# NUC123AE_v1 register map
File version: 1.0
Registers are 32-bit, read-write, reset 0x0 unless marked. A register's access mark holds for its fields unless they carry their own. Offsets are from the block's base; [hi:lo] are bit positions; {n}, {i} and the like mark numbered series; 'fields as' and 'values as' point back to an identical list.

## GP (part 1 of 2) — GP Register Map
Base 0x50004000
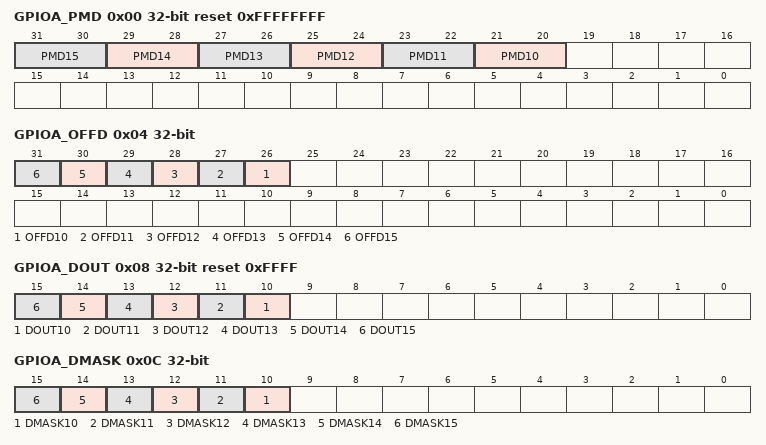
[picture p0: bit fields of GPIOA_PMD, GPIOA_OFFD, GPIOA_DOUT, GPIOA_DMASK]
0x00 GPIOA_PMD reset 0xFFFFFFFF — GPIO Port A Pin I/O Mode Control
  [all] fields
    0=GPIO port [n] pin is in INPUT mode; 1=GPIO port [n] pin is in OUTPUT mode; 2=GPIO port [n] pin is in Open-Drain mode; 3=GPIO port [n] pin is in Quasi-bidirectional mode
  [2n+1:2n] PMD{n} (n=10..15) — GPIOx I/O Pin[n] Mode Control. Determine each I/O type of GPIOx pins. Note: GPIOA: valid n are 15~10. Others are reserved. GPIOB: valid n are 15~12, 10~0. Others are reserved. GPIOC: valid n are 13~8, 5~0. Others are reserved. GPIOD: valid n are 11~8, 5~0. Others are reserved. GPIOF: valid n are 3~0. Others are reserved.
0x04 GPIOA_OFFD — GPIO Port A Pin OFF Digital Enable
  [all] fields
    0=IO digital input path Enabled; 1=IO digital input path Disabled (digital input tied to low)
  [n+16] OFFD{n} (n=10..15) — GPIOx Pin[n] OFF Digital Input Path Enable. Each of these bits is used to control if the input path of corresponding GPIO pin is disabled. If input is analog signal, user can OFF digital input path to avoid creepage. Notes: GPIOA: valid n are 15~10. Others are reserved. GPIOB: valid n are 15~12, 10~0. Others are reserved. GPIOC: valid n are 13~8, 5~0. Others are reserved. GPIOD: valid n are 11~8, 5~0. Others are reserved. GPIOF: valid n are 3~0. Others are reserved.
0x08 GPIOA_DOUT reset 0xFFFF — GPIO Port A Data Output Value
  [all] fields
    0=GPIO port [A/B/C/D/ F] Pin[n] will drive Low if the GPIO pin is configures as output, open-drain and quasi-mode; 1=GPIO port [A/B/C/DF] Pin[n] will drive High if the GPIO pin is configures as output, open-drain and quasi-mode
  [n] DOUT{n} (n=10..15) — GPIOx Pin[n] Output Value. Each of these bits control the status of a GPIO pin when the GPIO pin is configures as output, open-drain and quasi-mode. Note: GPIOA: valid n are 15~10. Others are reserved. GPIOB: valid n are 15~12, 10~0. Others are reserved. GPIOC: valid n are 13~8, 5~0. Others are reserved. GPIOD: valid n are 11~8, 5~0. Others are reserved. GPIOF: valid n are 3~0. Others are reserved.
0x0C GPIOA_DMASK — GPIO Port A Data Output Write Mask
  [all] fields
    0=The corresponding GPIOx_DOUT[n] bit can be updated; 1=The corresponding GPIOx_DOUT[n] bit is protected
  [n] DMASK{n} (n=10..15) — Port [A/B/C/D/ F] Data Output Write Mask. These bits are used to protect the corresponding register of GPIOx_DOUT bit[n]. When set the DMASK bit[n] to 1, the corresponding GPIOx_DOUT[n] bit is protected. The write signal is masked, write data to the protect bit is ignored. Note: This function only protect corresponding GPIOx_DOUT[n] bit, and will not protect corresponding bit control register (GPIOAx_DOUT, GPIOBx_DOUT, GPIOCx_DOUT, GPIODx_DOUT and GPIOFx_DOUT). Note: GPIOA: valid n are 15~10. Others are reserved. GPIOB: valid n are 15~12, 10~0. Others are reserved. GPIOC: valid n are 13~8, 5~0. Others are reserved. GPIOD: valid n are 11~8, 5~0. Others are reserved. GPIOF: valid n are 3~0. Others are reserved.
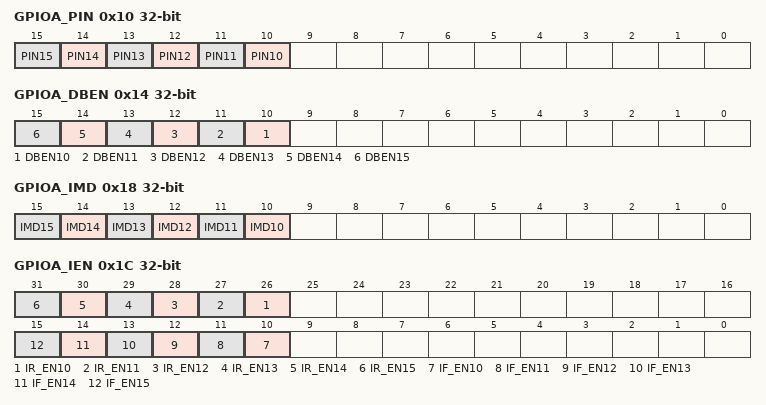
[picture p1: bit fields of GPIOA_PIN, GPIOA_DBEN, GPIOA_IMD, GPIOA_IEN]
0x10 GPIOA_PIN ro (reset mask 0xFFFF0000) — GPIO Port A Pin Value
  [n] PIN{n} (n=10..15) — Port [A/B/C/D/ F] Pin Values. Each bit of the register reflects the actual status of the respective GPIO pin If bit is 1, it indicates the corresponding pin status is high, else the pin status is low. Note: GPIOA: valid n are 15~10. Others are reserved. GPIOB: valid n are 15~12, 10~0. Others are reserved. GPIOC: valid n are 13~8, 5~0. Others are reserved. GPIOD: valid n are 11~8, 5~0. Others are reserved. GPIOF: valid n are 3~0. Others are reserved.
0x14 GPIOA_DBEN — GPIO Port A De-bounce Enable
  [all] fields
    0=The bit[n] de-bounce function is disabled; 1=The bit[n] de-bounce function is enabled
  [n] DBEN{n} (n=10..15) — Port [A/B/C/D/ F] Input Signal De-bounce Enable. DBEN[n]used to enable the de-bounce function for each corresponding bit. If the input signal pulse width can't be sampled by continuous two de-bounce sample cycle The input signal transition is seen as the signal bounce and will not trigger the interrupt. The de-bounce clock source is controlled by DBNCECON[4], one de-bounce sample cycle is controlled by DBNCECON[3:0]. The DBEN[n] is used for "edge-trigger" interrupt only, and ignored for "level trigger" interrupt. The de-bounce function is valid for edge triggered interrupt. If the interrupt mode is level triggered, the de-bounce enable bit is ignored. Note: GPIOA: valid n are 15~10. Others are reserved. GPIOB: valid n are 15~12, 10~0. Others are reserved. GPIOC: valid n are 13~8, 5~0. Others are reserved. GPIOD: valid n are 11~8, 5~0. Others are reserved. GPIOF: valid n are 3~0. Others are reserved.
0x18 GPIOA_IMD — GPIO Port A Interrupt Mode Control
  [all] fields
    0=Edge trigger interrupt; 1=Level trigger interrupt
  [n] IMD{n} (n=10..15) — Port [A/B/C/D/ F] Edge or Level Detection Interrupt Control. IMD[n] is used to control the interrupt is by level trigger or by edge trigger. If the interrupt is by edge trigger, the trigger source can be controlled by de-bounce. If the interrupt is by level trigger, the input source is sampled by one HCLK clock and generates the interrupt. If pin is set as the level trigger interrupt, only one level can be set on the registers GPIOx_IEN. If set both the level to trigger interrupt, the setting is ignored and no interrupt will occur. The de-bounce function is valid for edge triggered interrupt. If the interrupt mode is level triggered, the de-bounce enable bit is ignored. Note: GPIOA: Valid n are 15~10. Others are reserved. GPIOB: Valid n are 15~12, 10~0. Others are reserved. GPIOC: Valid n are 13~8, 5~0. Others are reserved. GPIOD: Valid n are 11~8, 5~0. Others are reserved. GPIOF: Valid n are 3~0. Others are reserved.
0x1C GPIOA_IEN — GPIO Port A Interrupt Enable
  [n+16] IR_EN{n} (n=10..15) — Port [A/B/C/D/ F] Interrupt Enable by Input Rising Edge or Input Level High. IR_EN[n] is used to enable the interrupt for each of the corresponding input GPIO_PIN[n]. Set bit to 1 also enable the pin wake-up function. When the IR_EN[n] bit is set to 1: If the interrupt is level triggered, the input PIN[n] state at level "high" will generate the interrupt. If the interrupt is edge triggered, the input PIN[n] state changes from "low-to-high" will generate the interrupt. Note: GPIOA: Valid n are 15~10. Others are reserved. GPIOB: Valid n are 15~12, 10~0. Others are reserved. GPIOC: Valid n are 13~8, 5~0. Others are reserved. GPIOD: Valid n are 11~8, 5~0. Others are reserved. GPIOF: Valid n are 3~0. Others are reserved.
    0=PIN[n] level-high or low-to-high interrupt Disabled; 1=PIN[n] level-high or low-to-high interrupt Enabled
  [n] IF_EN{n} (n=10..15) — Port [A/B/C/D/ F] Interrupt Enable by Input Falling Edge or Input Level Low. IF_EN[n] is used to enable the interrupt for each of the corresponding input GPIO_PIN[n]. Set bit to 1 also enable the pin wake-up function. When set the IF_EN[n] bit to 1: If the interrupt is level triggered, the input PIN[n] state at level "low" will generate the interrupt. If the interrupt is edge triggered, the input PIN[n] state changes from "high-to-low" will generate the interrupt. Note: GPIOA: Valid n are 15~10. Others are reserved. GPIOB: Valid n are 15~12, 10~0. Others are reserved. GPIOC: Valid n are 13~8, 5~0. Others are reserved. GPIOD: Valid n are 11~8, 5~0. Others are reserved. GPIOF: Valid n are 3~0. Others are reserved.
    0=PIN[n] state low-level or high-to-low change interrupt Disabled; 1=PIN[n] state low-level or high-to-low change interrupt Enabled
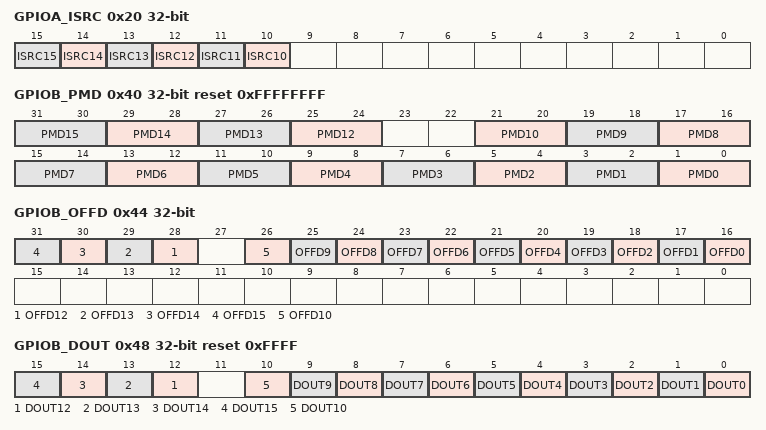
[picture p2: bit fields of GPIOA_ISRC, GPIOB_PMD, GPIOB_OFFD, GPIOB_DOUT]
0x20 GPIOA_ISRC — GPIO Port A Interrupt Trigger Source Indicator
  [all] fields
    0=No interrupt at GPIOx[n]. No action; 1=Indicates GPIOx[n] generate an interrupt. Clear the corresponding pending interrupt
  [n] ISRC{n} (n=10..15) — Port [A/B/C/D/ F] Interrupt Trigger Source Indicator. Read: Note: GPIOA: Valid n are 15~10. Others are reserved. GPIOB: Valid n are 15~12, 10~0. Others are reserved. GPIOC: Valid n are 13~8, 5~0. Others are reserved. GPIOD: Valid n are 11~8, 5~0. Others are reserved. GPIOF: Valid n are 3~0. Others are reserved.
0x40 GPIOB_PMD reset 0xFFFFFFFF — GPIO Port B Pin I/O Mode Control
  [all] fields
    values as the fields of GPIOA_PMD
  [2n+1:2n] PMD{n} (n=12..15) — GPIOx I/O Pin[n] Mode Control. Determine each I/O type of GPIOx pins. Note: GPIOA: valid n are 15~10. Others are reserved. GPIOB: valid n are 15~12, 10~0. Others are reserved. GPIOC: valid n are 13~8, 5~0. Others are reserved. GPIOD: valid n are 11~8, 5~0. Others are reserved. GPIOF: valid n are 3~0. Others are reserved.
  [2n+1:2n] PMD{n} (n=0..10) — GPIOx I/O Pin[n] Mode Control. Determine each I/O type of GPIOx pins. Note: GPIOA: valid n are 15~10. Others are reserved. GPIOB: valid n are 15~12, 10~0. Others are reserved. GPIOC: valid n are 13~8, 5~0. Others are reserved. GPIOD: valid n are 11~8, 5~0. Others are reserved. GPIOF: valid n are 3~0. Others are reserved.
0x44 GPIOB_OFFD — GPIO Port B Pin OFF Digital Enable
  [all] fields
    values as the fields of GPIOA_OFFD
  [n+16] OFFD{n} (n=12..15) — GPIOx Pin[n] OFF Digital Input Path Enable. Each of these bits is used to control if the input path of corresponding GPIO pin is disabled. If input is analog signal, user can OFF digital input path to avoid creepage. Notes: GPIOA: valid n are 15~10. Others are reserved. GPIOB: valid n are 15~12, 10~0. Others are reserved. GPIOC: valid n are 13~8, 5~0. Others are reserved. GPIOD: valid n are 11~8, 5~0. Others are reserved. GPIOF: valid n are 3~0. Others are reserved.
  [n+16] OFFD{n} (n=0..10) — GPIOx Pin[n] OFF Digital Input Path Enable. Each of these bits is used to control if the input path of corresponding GPIO pin is disabled. If input is analog signal, user can OFF digital input path to avoid creepage. Notes: GPIOA: valid n are 15~10. Others are reserved. GPIOB: valid n are 15~12, 10~0. Others are reserved. GPIOC: valid n are 13~8, 5~0. Others are reserved. GPIOD: valid n are 11~8, 5~0. Others are reserved. GPIOF: valid n are 3~0. Others are reserved.
0x48 GPIOB_DOUT reset 0xFFFF — GPIO Port B Data Output Value
  [all] fields
    values as the fields of GPIOA_DOUT
  [n] DOUT{n} (n=12..15) — GPIOx Pin[n] Output Value. Each of these bits control the status of a GPIO pin when the GPIO pin is configures as output, open-drain and quasi-mode. Note: GPIOA: valid n are 15~10. Others are reserved. GPIOB: valid n are 15~12, 10~0. Others are reserved. GPIOC: valid n are 13~8, 5~0. Others are reserved. GPIOD: valid n are 11~8, 5~0. Others are reserved. GPIOF: valid n are 3~0. Others are reserved.
  [n] DOUT{n} (n=0..10) — GPIOx Pin[n] Output Value. Each of these bits control the status of a GPIO pin when the GPIO pin is configures as output, open-drain and quasi-mode. Note: GPIOA: valid n are 15~10. Others are reserved. GPIOB: valid n are 15~12, 10~0. Others are reserved. GPIOC: valid n are 13~8, 5~0. Others are reserved. GPIOD: valid n are 11~8, 5~0. Others are reserved. GPIOF: valid n are 3~0. Others are reserved.
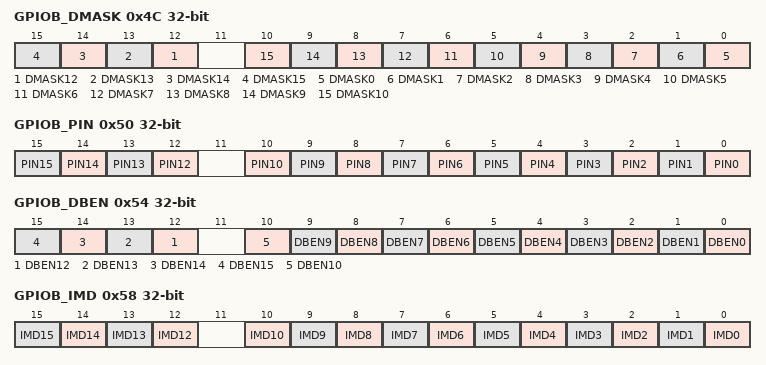
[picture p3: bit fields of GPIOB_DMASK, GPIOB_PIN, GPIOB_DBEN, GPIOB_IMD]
0x4C GPIOB_DMASK — GPIO Port B Data Output Write Mask
  [all] fields
    values as the fields of GPIOA_DMASK
  [n] DMASK{n} (n=12..15) — Port [A/B/C/D/ F] Data Output Write Mask. These bits are used to protect the corresponding register of GPIOx_DOUT bit[n]. When set the DMASK bit[n] to 1, the corresponding GPIOx_DOUT[n] bit is protected. The write signal is masked, write data to the protect bit is ignored. Note: This function only protect corresponding GPIOx_DOUT[n] bit, and will not protect corresponding bit control register (GPIOAx_DOUT, GPIOBx_DOUT, GPIOCx_DOUT, GPIODx_DOUT and GPIOFx_DOUT). Note: GPIOA: valid n are 15~10. Others are reserved. GPIOB: valid n are 15~12, 10~0. Others are reserved. GPIOC: valid n are 13~8, 5~0. Others are reserved. GPIOD: valid n are 11~8, 5~0. Others are reserved. GPIOF: valid n are 3~0. Others are reserved.
  [n] DMASK{n} (n=0..10) — Port [A/B/C/D/ F] Data Output Write Mask. These bits are used to protect the corresponding register of GPIOx_DOUT bit[n]. When set the DMASK bit[n] to 1, the corresponding GPIOx_DOUT[n] bit is protected. The write signal is masked, write data to the protect bit is ignored. Note: This function only protect corresponding GPIOx_DOUT[n] bit, and will not protect corresponding bit control register (GPIOAx_DOUT, GPIOBx_DOUT, GPIOCx_DOUT, GPIODx_DOUT and GPIOFx_DOUT). Note: GPIOA: valid n are 15~10. Others are reserved. GPIOB: valid n are 15~12, 10~0. Others are reserved. GPIOC: valid n are 13~8, 5~0. Others are reserved. GPIOD: valid n are 11~8, 5~0. Others are reserved. GPIOF: valid n are 3~0. Others are reserved.
0x50 GPIOB_PIN ro (reset mask 0xFFFF0000) — GPIO Port B Pin Value
  [n] PIN{n} (n=12..15) — Port [A/B/C/D/ F] Pin Values. Each bit of the register reflects the actual status of the respective GPIO pin If bit is 1, it indicates the corresponding pin status is high, else the pin status is low. Note: GPIOA: valid n are 15~10. Others are reserved. GPIOB: valid n are 15~12, 10~0. Others are reserved. GPIOC: valid n are 13~8, 5~0. Others are reserved. GPIOD: valid n are 11~8, 5~0. Others are reserved. GPIOF: valid n are 3~0. Others are reserved.
  [n] PIN{n} (n=0..10) — Port [A/B/C/D/ F] Pin Values. Each bit of the register reflects the actual status of the respective GPIO pin If bit is 1, it indicates the corresponding pin status is high, else the pin status is low. Note: GPIOA: valid n are 15~10. Others are reserved. GPIOB: valid n are 15~12, 10~0. Others are reserved. GPIOC: valid n are 13~8, 5~0. Others are reserved. GPIOD: valid n are 11~8, 5~0. Others are reserved. GPIOF: valid n are 3~0. Others are reserved.
0x54 GPIOB_DBEN — GPIO Port B De-bounce Enable
  [all] fields
    values as the fields of GPIOA_DBEN
  [n] DBEN{n} (n=12..15) — Port [A/B/C/D/ F] Input Signal De-bounce Enable. DBEN[n]used to enable the de-bounce function for each corresponding bit. If the input signal pulse width can't be sampled by continuous two de-bounce sample cycle The input signal transition is seen as the signal bounce and will not trigger the interrupt. The de-bounce clock source is controlled by DBNCECON[4], one de-bounce sample cycle is controlled by DBNCECON[3:0]. The DBEN[n] is used for "edge-trigger" interrupt only, and ignored for "level trigger" interrupt. The de-bounce function is valid for edge triggered interrupt. If the interrupt mode is level triggered, the de-bounce enable bit is ignored. Note: GPIOA: valid n are 15~10. Others are reserved. GPIOB: valid n are 15~12, 10~0. Others are reserved. GPIOC: valid n are 13~8, 5~0. Others are reserved. GPIOD: valid n are 11~8, 5~0. Others are reserved. GPIOF: valid n are 3~0. Others are reserved.
  [n] DBEN{n} (n=0..10) — Port [A/B/C/D/ F] Input Signal De-bounce Enable. DBEN[n]used to enable the de-bounce function for each corresponding bit. If the input signal pulse width can't be sampled by continuous two de-bounce sample cycle The input signal transition is seen as the signal bounce and will not trigger the interrupt. The de-bounce clock source is controlled by DBNCECON[4], one de-bounce sample cycle is controlled by DBNCECON[3:0]. The DBEN[n] is used for "edge-trigger" interrupt only, and ignored for "level trigger" interrupt. The de-bounce function is valid for edge triggered interrupt. If the interrupt mode is level triggered, the de-bounce enable bit is ignored. Note: GPIOA: valid n are 15~10. Others are reserved. GPIOB: valid n are 15~12, 10~0. Others are reserved. GPIOC: valid n are 13~8, 5~0. Others are reserved. GPIOD: valid n are 11~8, 5~0. Others are reserved. GPIOF: valid n are 3~0. Others are reserved.
0x58 GPIOB_IMD — GPIO Port B Interrupt Mode Control
  [all] fields
    0=Edge trigger interrupt; 1=Level trigger interrupt
  [n] IMD{n} (n=12..15) — Port [A/B/C/D/ F] Edge or Level Detection Interrupt Control. IMD[n] is used to control the interrupt is by level trigger or by edge trigger. If the interrupt is by edge trigger, the trigger source can be controlled by de-bounce. If the interrupt is by level trigger, the input source is sampled by one HCLK clock and generates the interrupt. If pin is set as the level trigger interrupt, only one level can be set on the registers GPIOx_IEN. If set both the level to trigger interrupt, the setting is ignored and no interrupt will occur. The de-bounce function is valid for edge triggered interrupt. If the interrupt mode is level triggered, the de-bounce enable bit is ignored. Note: GPIOA: Valid n are 15~10. Others are reserved. GPIOB: Valid n are 15~12, 10~0. Others are reserved. GPIOC: Valid n are 13~8, 5~0. Others are reserved. GPIOD: Valid n are 11~8, 5~0. Others are reserved. GPIOF: Valid n are 3~0. Others are reserved.
  [n] IMD{n} (n=0..10) — Port [A/B/C/D/ F] Edge or Level Detection Interrupt Control. IMD[n] is used to control the interrupt is by level trigger or by edge trigger. If the interrupt is by edge trigger, the trigger source can be controlled by de-bounce. If the interrupt is by level trigger, the input source is sampled by one HCLK clock and generates the interrupt. If pin is set as the level trigger interrupt, only one level can be set on the registers GPIOx_IEN. If set both the level to trigger interrupt, the setting is ignored and no interrupt will occur. The de-bounce function is valid for edge triggered interrupt. If the interrupt mode is level triggered, the de-bounce enable bit is ignored. Note: GPIOA: Valid n are 15~10. Others are reserved. GPIOB: Valid n are 15~12, 10~0. Others are reserved. GPIOC: Valid n are 13~8, 5~0. Others are reserved. GPIOD: Valid n are 11~8, 5~0. Others are reserved. GPIOF: Valid n are 3~0. Others are reserved.
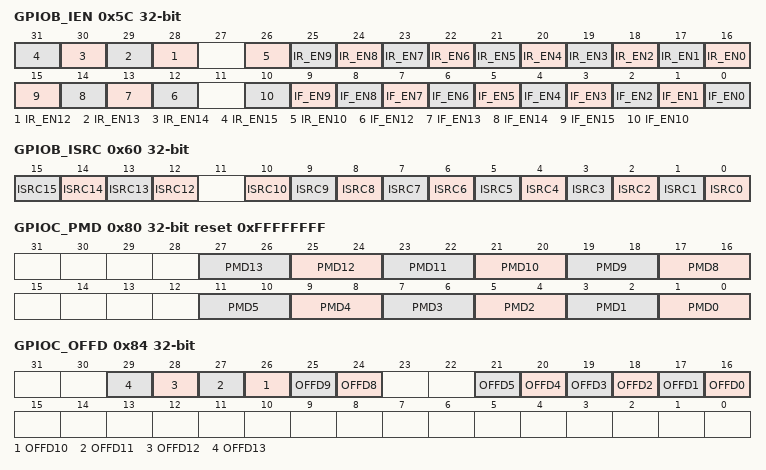
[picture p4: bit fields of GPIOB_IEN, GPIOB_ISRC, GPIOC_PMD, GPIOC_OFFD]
0x5C GPIOB_IEN — GPIO Port B Interrupt Enable
  [n+16] IR_EN{n} (n=12..15) — Port [A/B/C/D/ F] Interrupt Enable by Input Rising Edge or Input Level High. IR_EN[n] is used to enable the interrupt for each of the corresponding input GPIO_PIN[n]. Set bit to 1 also enable the pin wake-up function. When the IR_EN[n] bit is set to 1: If the interrupt is level triggered, the input PIN[n] state at level "high" will generate the interrupt. If the interrupt is edge triggered, the input PIN[n] state changes from "low-to-high" will generate the interrupt. Note: GPIOA: Valid n are 15~10. Others are reserved. GPIOB: Valid n are 15~12, 10~0. Others are reserved. GPIOC: Valid n are 13~8, 5~0. Others are reserved. GPIOD: Valid n are 11~8, 5~0. Others are reserved. GPIOF: Valid n are 3~0. Others are reserved.
    values as GPIOA_IEN.IR_EN10
  [n+16] IR_EN{n} (n=0..10) — Port [A/B/C/D/ F] Interrupt Enable by Input Rising Edge or Input Level High. IR_EN[n] is used to enable the interrupt for each of the corresponding input GPIO_PIN[n]. Set bit to 1 also enable the pin wake-up function. When the IR_EN[n] bit is set to 1: If the interrupt is level triggered, the input PIN[n] state at level "high" will generate the interrupt. If the interrupt is edge triggered, the input PIN[n] state changes from "low-to-high" will generate the interrupt. Note: GPIOA: Valid n are 15~10. Others are reserved. GPIOB: Valid n are 15~12, 10~0. Others are reserved. GPIOC: Valid n are 13~8, 5~0. Others are reserved. GPIOD: Valid n are 11~8, 5~0. Others are reserved. GPIOF: Valid n are 3~0. Others are reserved.
    values as GPIOA_IEN.IR_EN10
  [n] IF_EN{n} (n=12..15) — Port [A/B/C/D/ F] Interrupt Enable by Input Falling Edge or Input Level Low. IF_EN[n] is used to enable the interrupt for each of the corresponding input GPIO_PIN[n]. Set bit to 1 also enable the pin wake-up function. When set the IF_EN[n] bit to 1: If the interrupt is level triggered, the input PIN[n] state at level "low" will generate the interrupt. If the interrupt is edge triggered, the input PIN[n] state changes from "high-to-low" will generate the interrupt. Note: GPIOA: Valid n are 15~10. Others are reserved. GPIOB: Valid n are 15~12, 10~0. Others are reserved. GPIOC: Valid n are 13~8, 5~0. Others are reserved. GPIOD: Valid n are 11~8, 5~0. Others are reserved. GPIOF: Valid n are 3~0. Others are reserved.
    values as GPIOA_IEN.IF_EN10
  [n] IF_EN{n} (n=0..10) — Port [A/B/C/D/ F] Interrupt Enable by Input Falling Edge or Input Level Low. IF_EN[n] is used to enable the interrupt for each of the corresponding input GPIO_PIN[n]. Set bit to 1 also enable the pin wake-up function. When set the IF_EN[n] bit to 1: If the interrupt is level triggered, the input PIN[n] state at level "low" will generate the interrupt. If the interrupt is edge triggered, the input PIN[n] state changes from "high-to-low" will generate the interrupt. Note: GPIOA: Valid n are 15~10. Others are reserved. GPIOB: Valid n are 15~12, 10~0. Others are reserved. GPIOC: Valid n are 13~8, 5~0. Others are reserved. GPIOD: Valid n are 11~8, 5~0. Others are reserved. GPIOF: Valid n are 3~0. Others are reserved.
    values as GPIOA_IEN.IF_EN10
0x60 GPIOB_ISRC — GPIO Port B Interrupt Trigger Source Indicator
  [all] fields
    values as the fields of GPIOA_ISRC
  [n] ISRC{n} (n=12..15) — Port [A/B/C/D/ F] Interrupt Trigger Source Indicator. Read: Note: GPIOA: Valid n are 15~10. Others are reserved. GPIOB: Valid n are 15~12, 10~0. Others are reserved. GPIOC: Valid n are 13~8, 5~0. Others are reserved. GPIOD: Valid n are 11~8, 5~0. Others are reserved. GPIOF: Valid n are 3~0. Others are reserved.
  [n] ISRC{n} (n=0..10) — Port [A/B/C/D/ F] Interrupt Trigger Source Indicator. Read: Note: GPIOA: Valid n are 15~10. Others are reserved. GPIOB: Valid n are 15~12, 10~0. Others are reserved. GPIOC: Valid n are 13~8, 5~0. Others are reserved. GPIOD: Valid n are 11~8, 5~0. Others are reserved. GPIOF: Valid n are 3~0. Others are reserved.
0x80 GPIOC_PMD reset 0xFFFFFFFF — GPIO Port C Pin I/O Mode Control
  [all] fields
    values as the fields of GPIOA_PMD
  [2n+1:2n] PMD{n} (n=8..13) — GPIOx I/O Pin[n] Mode Control. Determine each I/O type of GPIOx pins. Note: GPIOA: valid n are 15~10. Others are reserved. GPIOB: valid n are 15~12, 10~0. Others are reserved. GPIOC: valid n are 13~8, 5~0. Others are reserved. GPIOD: valid n are 11~8, 5~0. Others are reserved. GPIOF: valid n are 3~0. Others are reserved.
  [2n+1:2n] PMD{n} (n=0..5) — GPIOx I/O Pin[n] Mode Control. Determine each I/O type of GPIOx pins. Note: GPIOA: valid n are 15~10. Others are reserved. GPIOB: valid n are 15~12, 10~0. Others are reserved. GPIOC: valid n are 13~8, 5~0. Others are reserved. GPIOD: valid n are 11~8, 5~0. Others are reserved. GPIOF: valid n are 3~0. Others are reserved.
0x84 GPIOC_OFFD — GPIO Port C Pin OFF Digital Enable
  [all] fields
    values as the fields of GPIOA_OFFD
  [n+16] OFFD{n} (n=8..13) — GPIOx Pin[n] OFF Digital Input Path Enable. Each of these bits is used to control if the input path of corresponding GPIO pin is disabled. If input is analog signal, user can OFF digital input path to avoid creepage. Notes: GPIOA: valid n are 15~10. Others are reserved. GPIOB: valid n are 15~12, 10~0. Others are reserved. GPIOC: valid n are 13~8, 5~0. Others are reserved. GPIOD: valid n are 11~8, 5~0. Others are reserved. GPIOF: valid n are 3~0. Others are reserved.
  [n+16] OFFD{n} (n=0..5) — GPIOx Pin[n] OFF Digital Input Path Enable. Each of these bits is used to control if the input path of corresponding GPIO pin is disabled. If input is analog signal, user can OFF digital input path to avoid creepage. Notes: GPIOA: valid n are 15~10. Others are reserved. GPIOB: valid n are 15~12, 10~0. Others are reserved. GPIOC: valid n are 13~8, 5~0. Others are reserved. GPIOD: valid n are 11~8, 5~0. Others are reserved. GPIOF: valid n are 3~0. Others are reserved.
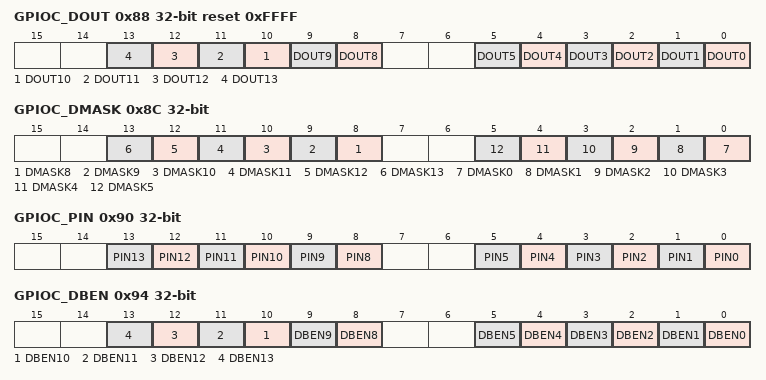
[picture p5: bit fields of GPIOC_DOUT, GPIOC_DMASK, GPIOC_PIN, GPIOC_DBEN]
0x88 GPIOC_DOUT reset 0xFFFF — GPIO Port C Data Output Value
  [all] fields
    values as the fields of GPIOA_DOUT
  [n] DOUT{n} (n=8..13) — GPIOx Pin[n] Output Value. Each of these bits control the status of a GPIO pin when the GPIO pin is configures as output, open-drain and quasi-mode. Note: GPIOA: valid n are 15~10. Others are reserved. GPIOB: valid n are 15~12, 10~0. Others are reserved. GPIOC: valid n are 13~8, 5~0. Others are reserved. GPIOD: valid n are 11~8, 5~0. Others are reserved. GPIOF: valid n are 3~0. Others are reserved.
  [n] DOUT{n} (n=0..5) — GPIOx Pin[n] Output Value. Each of these bits control the status of a GPIO pin when the GPIO pin is configures as output, open-drain and quasi-mode. Note: GPIOA: valid n are 15~10. Others are reserved. GPIOB: valid n are 15~12, 10~0. Others are reserved. GPIOC: valid n are 13~8, 5~0. Others are reserved. GPIOD: valid n are 11~8, 5~0. Others are reserved. GPIOF: valid n are 3~0. Others are reserved.
0x8C GPIOC_DMASK — GPIO Port C Data Output Write Mask
  [all] fields
    values as the fields of GPIOA_DMASK
  [n] DMASK{n} (n=8..13) — Port [A/B/C/D/ F] Data Output Write Mask. These bits are used to protect the corresponding register of GPIOx_DOUT bit[n]. When set the DMASK bit[n] to 1, the corresponding GPIOx_DOUT[n] bit is protected. The write signal is masked, write data to the protect bit is ignored. Note: This function only protect corresponding GPIOx_DOUT[n] bit, and will not protect corresponding bit control register (GPIOAx_DOUT, GPIOBx_DOUT, GPIOCx_DOUT, GPIODx_DOUT and GPIOFx_DOUT). Note: GPIOA: valid n are 15~10. Others are reserved. GPIOB: valid n are 15~12, 10~0. Others are reserved. GPIOC: valid n are 13~8, 5~0. Others are reserved. GPIOD: valid n are 11~8, 5~0. Others are reserved. GPIOF: valid n are 3~0. Others are reserved.
  [n] DMASK{n} (n=0..5) — Port [A/B/C/D/ F] Data Output Write Mask. These bits are used to protect the corresponding register of GPIOx_DOUT bit[n]. When set the DMASK bit[n] to 1, the corresponding GPIOx_DOUT[n] bit is protected. The write signal is masked, write data to the protect bit is ignored. Note: This function only protect corresponding GPIOx_DOUT[n] bit, and will not protect corresponding bit control register (GPIOAx_DOUT, GPIOBx_DOUT, GPIOCx_DOUT, GPIODx_DOUT and GPIOFx_DOUT). Note: GPIOA: valid n are 15~10. Others are reserved. GPIOB: valid n are 15~12, 10~0. Others are reserved. GPIOC: valid n are 13~8, 5~0. Others are reserved. GPIOD: valid n are 11~8, 5~0. Others are reserved. GPIOF: valid n are 3~0. Others are reserved.
0x90 GPIOC_PIN ro (reset mask 0xFFFF0000) — GPIO Port C Pin Value
  [n] PIN{n} (n=8..13) — Port [A/B/C/D/ F] Pin Values. Each bit of the register reflects the actual status of the respective GPIO pin If bit is 1, it indicates the corresponding pin status is high, else the pin status is low. Note: GPIOA: valid n are 15~10. Others are reserved. GPIOB: valid n are 15~12, 10~0. Others are reserved. GPIOC: valid n are 13~8, 5~0. Others are reserved. GPIOD: valid n are 11~8, 5~0. Others are reserved. GPIOF: valid n are 3~0. Others are reserved.
  [n] PIN{n} (n=0..5) — Port [A/B/C/D/ F] Pin Values. Each bit of the register reflects the actual status of the respective GPIO pin If bit is 1, it indicates the corresponding pin status is high, else the pin status is low. Note: GPIOA: valid n are 15~10. Others are reserved. GPIOB: valid n are 15~12, 10~0. Others are reserved. GPIOC: valid n are 13~8, 5~0. Others are reserved. GPIOD: valid n are 11~8, 5~0. Others are reserved. GPIOF: valid n are 3~0. Others are reserved.
0x94 GPIOC_DBEN — GPIO Port C De-bounce Enable
  [all] fields
    values as the fields of GPIOA_DBEN
  [n] DBEN{n} (n=8..13) — Port [A/B/C/D/ F] Input Signal De-bounce Enable. DBEN[n]used to enable the de-bounce function for each corresponding bit. If the input signal pulse width can't be sampled by continuous two de-bounce sample cycle The input signal transition is seen as the signal bounce and will not trigger the interrupt. The de-bounce clock source is controlled by DBNCECON[4], one de-bounce sample cycle is controlled by DBNCECON[3:0]. The DBEN[n] is used for "edge-trigger" interrupt only, and ignored for "level trigger" interrupt. The de-bounce function is valid for edge triggered interrupt. If the interrupt mode is level triggered, the de-bounce enable bit is ignored. Note: GPIOA: valid n are 15~10. Others are reserved. GPIOB: valid n are 15~12, 10~0. Others are reserved. GPIOC: valid n are 13~8, 5~0. Others are reserved. GPIOD: valid n are 11~8, 5~0. Others are reserved. GPIOF: valid n are 3~0. Others are reserved.
  [n] DBEN{n} (n=0..5) — Port [A/B/C/D/ F] Input Signal De-bounce Enable. DBEN[n]used to enable the de-bounce function for each corresponding bit. If the input signal pulse width can't be sampled by continuous two de-bounce sample cycle The input signal transition is seen as the signal bounce and will not trigger the interrupt. The de-bounce clock source is controlled by DBNCECON[4], one de-bounce sample cycle is controlled by DBNCECON[3:0]. The DBEN[n] is used for "edge-trigger" interrupt only, and ignored for "level trigger" interrupt. The de-bounce function is valid for edge triggered interrupt. If the interrupt mode is level triggered, the de-bounce enable bit is ignored. Note: GPIOA: valid n are 15~10. Others are reserved. GPIOB: valid n are 15~12, 10~0. Others are reserved. GPIOC: valid n are 13~8, 5~0. Others are reserved. GPIOD: valid n are 11~8, 5~0. Others are reserved. GPIOF: valid n are 3~0. Others are reserved.
